# STM32F100 register map
File version: 1.1
CPU: CM3 r1p1, little endian, no MPU, no FPU, 4 interrupt priority bits
Registers are 32-bit, read-write, reset 0x0 unless marked. A register's access mark holds for its fields unless they carry their own. Offsets are from the block's base; [hi:lo] are bit positions; {n}, {i} and the like mark numbered series; 'fields as' and 'values as' point back to an identical list.

## FSMC — Flexible static memory controller
Base 0xA0000000
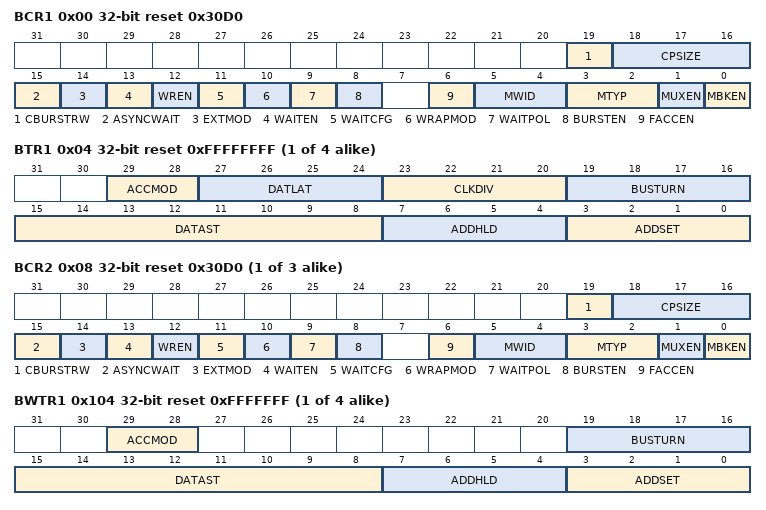
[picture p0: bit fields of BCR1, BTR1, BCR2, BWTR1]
0x00 BCR1 reset 0x30D0 — SRAM/NOR-Flash chip-select control register 1
  [19] CBURSTRW
    0=Disabled (Write operations are always performed in asynchronous mode); 1=Enabled (Write operations are performed in synchronous mode)
  [18:16] CPSIZE — CRAM page size
    0=No burst split when crossing page boundary; 1=Bytes128 (128 bytes CRAM page size); 2=Bytes256 (256 bytes CRAM page size); 3=Bytes512 (512 bytes CRAM page size); 4=Bytes1024 (1024 bytes CRAM page size)
  [15] ASYNCWAIT
    0=Disabled (Wait signal not used in asynchronous mode); 1=Enabled (Wait signal used even in asynchronous mode)
  [14] EXTMOD
    0=Disabled (Values inside the FMC_BWTR are not taken into account); 1=Enabled (Values inside the FMC_BWTR are taken into account)
  [13] WAITEN
    0=Disabled (Values inside the FMC_BWTR are taken into account); 1=Enabled (NWAIT signal enabled)
  [12] WREN
    0=Disabled (Write operations disabled for the bank by the FMC); 1=Enabled (Write operations enabled for the bank by the FMC)
  [11] WAITCFG
    0=BeforeWaitState (NWAIT signal is active one data cycle before wait state); 1=DuringWaitState (NWAIT signal is active during wait state)
  [10] WRAPMOD
    0=Disabled (Direct wrapped burst is not enabled); 1=Enabled (Direct wrapped burst is enabled)
  [9] WAITPOL
    0=ActiveLow (NWAIT active low); 1=ActiveHigh (NWAIT active high)
  [8] BURSTEN
    0=Disabled (Burst mode disabled); 1=Enabled (Burst mode enabled)
  [6] FACCEN
    0=Disabled (Corresponding NOR Flash memory access is disabled); 1=Enabled (Corresponding NOR Flash memory access is enabled)
  [5:4] MWID
    0=Bits8 (Memory data bus width 8 bits); 1=Bits16 (Memory data bus width 16 bits); 2=Bits32 (Memory data bus width 32 bits)
  [3:2] MTYP
    0=SRAM (SRAM memory type); 1=PSRAM (PSRAM (CRAM) memory type); 2=Flash (NOR Flash/OneNAND Flash)
  [1] MUXEN
    0=Disabled (Address/Data non-multiplexed); 1=Enabled (Address/Data multiplexed on databus)
  [0] MBKEN
    0=Disabled (Corresponding memory bank is disabled); 1=Enabled (Corresponding memory bank is enabled)
0x04 BTR{i} (i=1..4; step 0x8) reset 0xFFFFFFFF — SRAM/NOR-Flash chip-select timing register {i}
  [29:28] ACCMOD
    0=A (Access mode A); 1=B (Access mode B); 2=C (Access mode C); 3=D (Access mode D)
  [27:24] DATLAT
  [23:20] CLKDIV range 1..15
  [19:16] BUSTURN
  [15:8] DATAST range 1..255
  [7:4] ADDHLD range 1..15
  [3:0] ADDSET
0x08 BCR{i} (i=2..4; step 0x8) reset 0x30D0 — SRAM/NOR-Flash chip-select control register {i}
  fields as BCR1
{0xFC+8i} BWTR{i} (i=1..4) reset 0xFFFFFFF — SRAM/NOR-Flash write timing registers {i}
  [29:28] ACCMOD
    values as BTR{i}.ACCMOD
  [19:16] BUSTURN — Bus turnaround phase duration
  [15:8] DATAST range 1..255
  [7:4] ADDHLD range 1..15
  [3:0] ADDSET

## PWR — Power control
Base 0x40007000
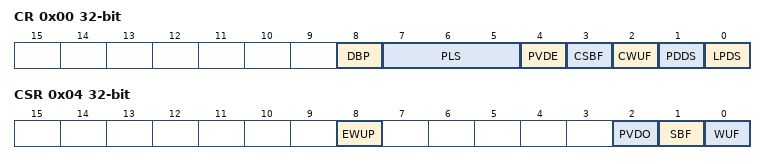
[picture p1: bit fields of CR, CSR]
0x00 CR — Power control register (PWR_CR)
  [8] DBP — Disable Backup Domain write protection
  [7:5] PLS — PVD Level Selection
  [4] PVDE — Power Voltage Detector Enable
  [3] CSBF — Clear STANDBY Flag
  [2] CWUF — Clear Wake-up Flag
  [1] PDDS — Power Down Deep Sleep
    0=STOP_MODE (Enter Stop mode when the CPU enters deepsleep); 1=STANDBY_MODE (Enter Standby mode when the CPU enters deepsleep)
  [0] LPDS — Low Power Deep Sleep
0x04 CSR access per field — Power control register (PWR_CR)
  [8] EWUP rw — Enable WKUP pin
  [2] PVDO ro — PVD Output
  [1] SBF ro — STANDBY Flag
  [0] WUF ro — Wake-Up Flag

## GPIOA — General purpose I/O
Base 0x40010800
Same registers: GPIOB 0x40010C00, GPIOC 0x40011000, GPIOD 0x40011400, GPIOE 0x40011800, GPIOF 0x40011C00, GPIOG 0x40012000
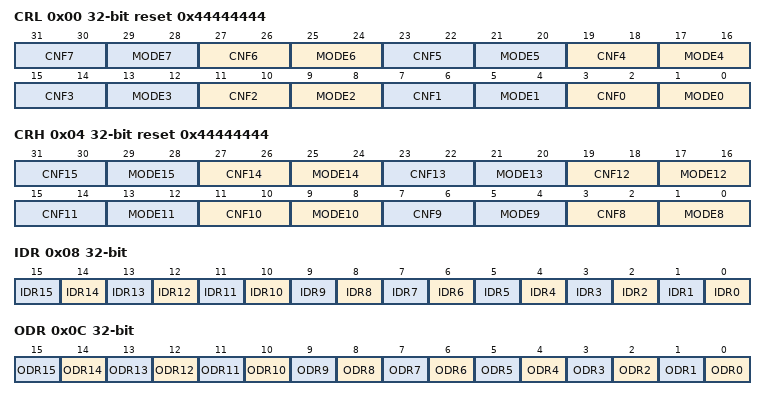
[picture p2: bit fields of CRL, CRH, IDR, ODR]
0x00 CRL reset 0x44444444 — Port configuration register low (GPIOn_CRL)
  [4n+3:4n+2] CNF{n} (n=0..7) — Port n.{n} configuration bits
    0=PushPull (Analog mode / Push-Pull mode); 1=OpenDrain (Floating input (reset state) / Open Drain-Mode); 2=AltPushPull (Input with pull-up/pull-down / Alternate Function Push-Pull Mode); 3=AltOpenDrain (Alternate Function Open-Drain Mode)
  [4n+1:4n] MODE{n} (n=0..7) — Port n.{n} mode bits
    0=Input mode (reset state); 1=Output mode 10 MHz; 2=Output2 (Output mode 2 MHz); 3=Output50 (Output mode 50 MHz)
0x04 CRH reset 0x44444444 — Port configuration register high (GPIOn_CRL)
  [4n-29:4n-30] CNF{n} (n=8..15) — Port n.{n} configuration bits
    values as CRL.CNF0
  [4n-31:4n-32] MODE{n} (n=8..15) — Port n.{n} mode bits
    values as CRL.MODE0
0x08 IDR ro — Port input data register (GPIOn_IDR)
  [n] IDR{n} (n=0..15) — Port input data
    0=Low (Input is logic low); 1=High (Input is logic high)
0x0C ODR — Port output data register (GPIOn_ODR)
  [n] ODR{n} (n=0..15) — Port output data
    0=Low (Set output to logic low); 1=High (Set output to logic high)
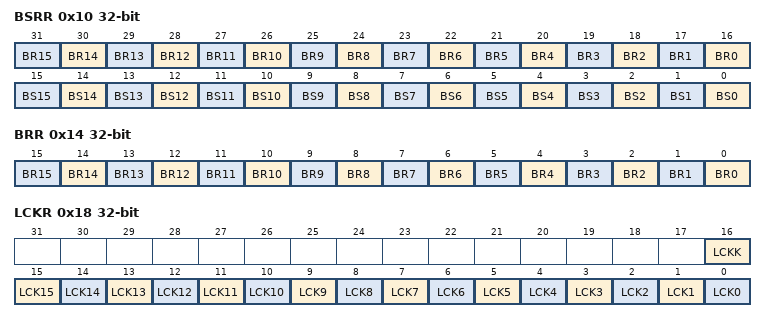
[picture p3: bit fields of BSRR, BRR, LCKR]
0x10 BSRR wo — Port bit set/reset register (GPIOn_BSRR)
  [n+16] BR{n} (n=0..15) — Reset bit {n}
    1=Resets the corresponding ODRx bit
  [n] BS{n} (n=0..15) — Set bit {n}
    1=Set (Sets the corresponding ODRx bit)
0x14 BRR wo — Port bit reset register (GPIOn_BRR)
  [n] BR{n} (n=0..15) — Reset bit {n}
    0=No action on the corresponding ODx bit; 1=Reset the ODx bit
0x18 LCKR — Port configuration lock register
  [16] LCKK — Lock key
    0=NotActive (Port configuration lock key not active); 1=Active (Port configuration lock key active)
  [n] LCK{n} (n=0..15) — Port A Lock bit {n}
    0=Unlocked (Port configuration not locked); 1=Locked (Port configuration locked)
